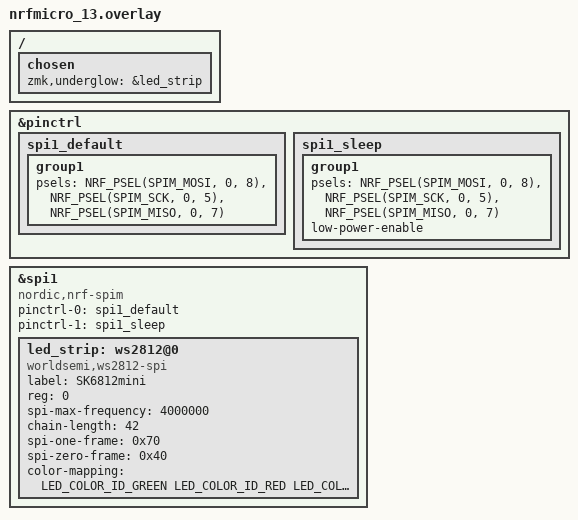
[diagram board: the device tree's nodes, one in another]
#include <dt-bindings/led/led.h>

// 1. Описываем пины через pinctrl
&pinctrl {
    spi1_default: spi1_default {
        group1 {
            // Здесь мы указываем mosi и sck (miso для светодиодов обычно не нужен, но раз был 7 — добавим)
            // Формат: <NRF_PSEL(функция, порт, пин)>
            // nrfmicro_13 почти всегда использует порт 0
            psels = <NRF_PSEL(SPIM_MOSI, 0, 8)>,
                    <NRF_PSEL(SPIM_SCK, 0, 5)>,
                    <NRF_PSEL(SPIM_MISO, 0, 7)>;
        };
    };

    spi1_sleep: spi1_sleep {
        group1 {
            psels = <NRF_PSEL(SPIM_MOSI, 0, 8)>,
                    <NRF_PSEL(SPIM_SCK, 0, 5)>,
                    <NRF_PSEL(SPIM_MISO, 0, 7)>;
            low-power-enable;
        };
    };
};

// 2. Обновляем блок SPI
&spi1 {
	compatible = "nordic,nrf-spim";
	status = "okay";

    // Указываем ссылки на созданные выше настройки пинов
    pinctrl-0 = <&spi1_default>;
    pinctrl-1 = <&spi1_sleep>;
    pinctrl-names = "default", "sleep";

	led_strip: ws2812@0 {
		compatible = "worldsemi,ws2812-spi";
		label = "SK6812mini";

		reg = <0>;
		spi-max-frequency = <4000000>;

		chain-length = <42>;
		spi-one-frame = <0x70>;
		spi-zero-frame = <0x40>;

		color-mapping = <LED_COLOR_ID_GREEN
                         LED_COLOR_ID_RED
                         LED_COLOR_ID_BLUE>;
	};
};

/ {
	chosen {
		zmk,underglow = &led_strip;
	};
};
